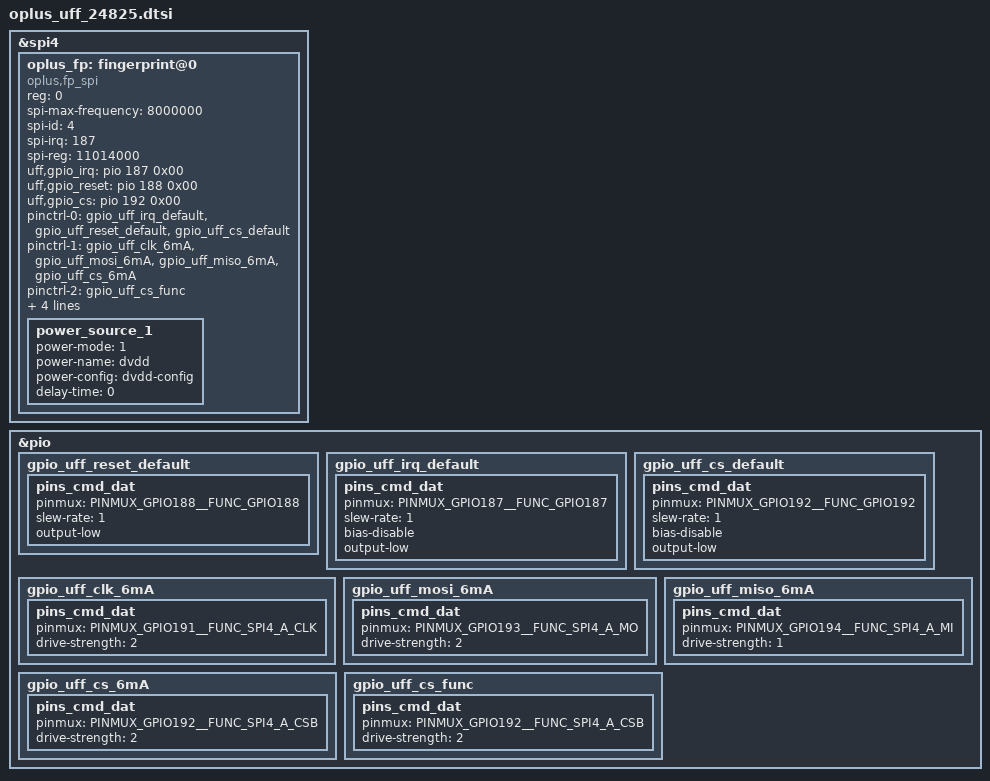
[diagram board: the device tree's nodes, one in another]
// SPDX-License-Identifier: GPL-2.0-only
/*
* Copyright (C) 2021-2025 Oplus. All rights reserved.
*/
#include <dt-bindings/iio/mt635x-auxadc.h>
#include <dt-bindings/pinctrl/mt6373-pinfunc.h>
#include <dt-bindings/pinctrl/mt65xx.h>

/* UFF dts config at 2023.5.19
 *
 * fp vendor:
 *   jiiov: JV0307(only one fp device)
 */

/* FINGERPRINT start */
&spi4 {
#address-cells = <1>;
#size-cells = <0>;
status = "okay";
oplus_fp: fingerprint@0 {
		compatible = "oplus,fp_spi";
		reg = <0>;
		spi-max-frequency = <8000000>;
		spi-id = <4>;
		spi-irq = <187>;
		spi-reg = <11014000>;
		uff,gpio_irq = <&pio 187 0x00>;
		uff,gpio_reset = <&pio 188 0x00>;
		uff,gpio_cs = <&pio 192 0x00>;
		pinctrl-names = "default", "fp_spi_driver", "fp_cs_func";
		pinctrl-0 = <&gpio_uff_irq_default>, <&gpio_uff_reset_default>, <&gpio_uff_cs_default>;
		pinctrl-1 = <&gpio_uff_clk_6mA>, <&gpio_uff_mosi_6mA>, <&gpio_uff_miso_6mA>, <&gpio_uff_cs_6mA>;
		pinctrl-2 = <&gpio_uff_cs_func>;
		dvdd-supply = <&mt6373_vfp>;
		dvdd-config = <3000000 3000000 120000>;
                optical_irq_disable_flag = <1>;
		power-num = <1>;
		status = "okay";
		power_source_1 {
			power-mode = <1>;
			power-name = "dvdd";
			power-config = "dvdd-config";
			delay-time = <0>;
		};
	};
};

&pio{
gpio_uff_reset_default: gpio_uff_reset_default {
				pins_cmd_dat {
					pinmux = <PINMUX_GPIO188__FUNC_GPIO188>;
					slew-rate = <1>;
					output-low;
				};
			};
gpio_uff_irq_default: gpio_uff_irq_default {
				pins_cmd_dat {
					pinmux = <PINMUX_GPIO187__FUNC_GPIO187>;
					slew-rate = <1>;
					bias-disable;
					output-low;
				};
			};
gpio_uff_cs_default: gpio_uff_cs_default {
				pins_cmd_dat {
					pinmux = <PINMUX_GPIO192__FUNC_GPIO192>;
					slew-rate = <1>;
					bias-disable;
					output-low;
				};
			};
gpio_uff_clk_6mA: gpio_uff_clk_6mA {
				pins_cmd_dat {
					pinmux = <PINMUX_GPIO191__FUNC_SPI4_A_CLK>;
					drive-strength = <2>;
				};
			};
gpio_uff_mosi_6mA: gpio_uff_mosi_6mA {
				pins_cmd_dat {
					pinmux = <PINMUX_GPIO193__FUNC_SPI4_A_MO>;
					drive-strength = <2>;
				};
			};
gpio_uff_miso_6mA: gpio_uff_miso_6mA {
				pins_cmd_dat {
					pinmux = <PINMUX_GPIO194__FUNC_SPI4_A_MI>;
					drive-strength = <1>;
				};
			};
gpio_uff_cs_6mA: gpio_uff_cs_6mA {
				pins_cmd_dat {
					pinmux = <PINMUX_GPIO192__FUNC_SPI4_A_CSB>;
					drive-strength = <2>;
				};
			};
gpio_uff_cs_func: gpio_uff_cs_func {
					pins_cmd_dat {
					pinmux = <PINMUX_GPIO192__FUNC_SPI4_A_CSB>;
					drive-strength = <2>;
				};
			};
};
/* FINGERPRINT end */
